AUTOSAR XML (schema 00048)
package /SecurityArchitecture/ComponentTypes
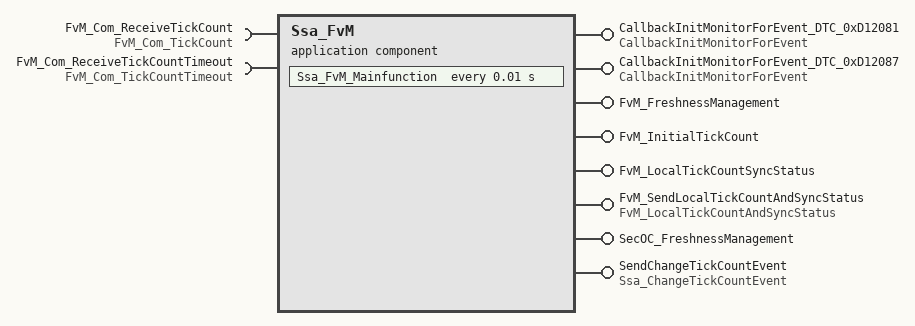
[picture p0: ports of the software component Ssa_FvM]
  application sw component type Ssa_FvM
    8 x provide port:
      CallbackInitMonitorForEvent_DTC_0xD12081: server-com-spec{operation=InitMonitorForEvent, queue-length=1}, provided-interface=CallbackInitMonitorForEvent  # Notifies that this event is cleared, or that the operation (monitoring) cycle restarts. Connect to corresponding event of Dem. Configuration Variant(s): Not in VSM.
      CallbackInitMonitorForEvent_DTC_0xD12087: server-com-spec{operation=InitMonitorForEvent, queue-length=1}, provided-interface=CallbackInitMonitorForEvent  # Notifies that this event is cleared, or that the operation (monitoring) cycle restarts. Connect to corresponding event of Dem. Configuration Variant(s): Not in VSM.
      FvM_FreshnessManagement: provided-com-specs=[{operation=GetRxFreshness, queue-length=1}, {operation=GetTxFreshness, queue-length=1}], provided-interface=FvM_FreshnessManagement
      FvM_InitialTickCount: server-com-spec{operation=Set, queue-length=1}, provided-interface=FvM_InitialTickCount
      FvM_LocalTickCountSyncStatus: server-com-spec{operation=Get, queue-length=1}, provided-interface=FvM_LocalTickCountSyncStatus
      FvM_SendLocalTickCountAndSyncStatus: nonqueued-sender-com-spec{data-element=Data, init-value=constant-reference=Ssa_Init_LocalTickCountAndSyncStatus}, provided-interface=FvM_LocalTickCountAndSyncStatus
      SecOC_FreshnessManagement: provided-interface=SecOC_FreshnessManagement  # Calculates the tick-count as freshness for Rx and Tx PDUs.
        provided-com-specs:
          operation=GetRxFreshness, queue-length=1
          operation=GetTxFreshness, queue-length=1
          operation=GetTxFreshnessTruncData, queue-length=1
          operation=SPduTxConfirmation, queue-length=1
      SendChangeTickCountEvent: provided-interface=Ssa_ChangeTickCountEvent  # Configuration Variant(s): Not in VSM.
        provided-com-specs:
          data-element=Id, init-value=SSA_CHANGETICKCOUNTEVENTID_UNDEFINED
          data-element=TickCount, init-value=constant-reference=Ssa_Init_Zero_5Byte
    require port FvM_Com_ReceiveTickCount: nonqueued-receiver-com-spec{data-element=tickCount, filter=data-filter-type=ALWAYS, init-value=constant-reference=Ssa_Init_Zero_6Byte}, required-interface=FvM_Com_TickCount  # Configuration Variant(s): Not in VSM.
    require port FvM_Com_ReceiveTickCountTimeout: nonqueued-receiver-com-spec{data-element=state, filter=data-filter-type=ALWAYS, init-value=0}, required-interface=FvM_Com_TickCountTimeout  # Configuration Variant(s): Not in VSM.
    behavior Ssa_FvM_InternalBehavior: data-type-mapping=SSATypeMappingSet
      exclusive area FvM_ExclusiveArea
      ar-typed-per-instance-memorys:
        data LastSecuredTickCount: type=uint64
        data TickCount: type=uint64
      data received event DRT_Ssa_TimeM_Com_ReceiveTickCount_FvM_Com_ReceiveTickCount_tickCount: start-on-event=Ssa_FvM_Com_ReceiveTickCount, data=FvM_Com_ReceiveTickCount.tickCount
      data received event DRT_Ssa_FvM_Com_ReceiveTickCountTimeout_FvM_Com_ReceiveTickCountTimeout_state: start-on-event=Ssa_FvM_Com_ReceiveTickCountTimeout, data=FvM_Com_ReceiveTickCountTimeout.state
      5 x operation invoked event:
        OIT_Ssa_FvM_GetRxFreshness_FvM_FreshnessManagement_GetRxFreshness: start-on-event=Ssa_FvM_GetRxFreshness, operation=FvM_FreshnessManagement.GetRxFreshness
        OIT_Ssa_FvM_GetRxFreshness_SecOC_FreshnessManagement_GetRxFreshness: start-on-event=Ssa_FvM_GetRxFreshness, operation=SecOC_FreshnessManagement.GetRxFreshness
        OIT_Ssa_FvM_GetTxFreshness_FvM_FreshnessManagement_GetTxFreshness: start-on-event=Ssa_FvM_GetTxFreshness, operation=FvM_FreshnessManagement.GetTxFreshness
        OIT_Ssa_FvM_GetTxFreshness_SecOC_FreshnessManagement_GetTxFreshness: start-on-event=Ssa_FvM_GetTxFreshness, operation=SecOC_FreshnessManagement.GetTxFreshness
        OIT_Ssa_FvM_GetTxFreshnessTruncData_SecOC_FreshnessManagement_GetTxFreshnessTruncData: start-on-event=Ssa_FvM_GetTxFreshnessTruncData, operation=SecOC_FreshnessManagement.GetTxFreshnessTruncData
      init event Ssa_FvM_InitEvent: start-on-event=Ssa_FvM_Init
      4 x operation invoked event:
        OIT_FvM_InitialTickCount_Set_FvM_InitialTickCount_Set: start-on-event=Ssa_FvM_InitialTickCount_Set, operation=FvM_InitialTickCount.Set
        OIT_CallbackInitMonitorForEvent_DTC_0xD12081_InitMonitorForEvent_CallbackInitMonitorForEvent_DTC_0xD12081_InitMonitorForEvent: start-on-event=Ssa_FvM_InitMonitorForEvent_DTC_0xD12081, operation=CallbackInitMonitorForEvent_DTC_0xD12081.InitMonitorForEvent
        OIT_CallbackInitMonitorForEvent_DTC_0xD12087_InitMonitorForEvent_CallbackInitMonitorForEvent_DTC_0xD12087_InitMonitorForEvent: start-on-event=Ssa_FvM_InitMonitorForEvent_DTC_0xD12087, operation=CallbackInitMonitorForEvent_DTC_0xD12087.InitMonitorForEvent
        OIT_FvM_LocalTickCountSyncStatus_Get_FvM_LocalTickCountSyncStatus_Get: start-on-event=Ssa_FvM_LocalTickCountSyncStatus_Get, operation=FvM_LocalTickCountSyncStatus.Get
      timing event TMT_Ssa_FvM_Mainfunction: start-on-event=Ssa_FvM_Mainfunction, period=0.01
      operation invoked event OIT_Ssa_FvM_SPduTxConfirmation_SecOC_FreshnessManagement_SPduTxConfirmation: start-on-event=Ssa_FvM_SPduTxConfirmation, operation=SecOC_FreshnessManagement.SPduTxConfirmation
      explicit-inter-runnable-variables:
        data FvM_IrvCountUpSecTimeMsg: type=uint8, init-value=0
        data FvM_IrvFirstTickCountMessageAfterStartUpReceived: type=boolean, init-value=0
        data FvM_IrvTickCountSyncState: type=Ssa_TickCountSyncStateType, init-value=0
      12 x runnable:
        Ssa_FvM_Com_ReceiveTickCount: can-enter-exclusive-area=FvM_ExclusiveArea  # Check if the received time is valid. If it is valid, update the Local Time Base. Function is called when the Time Base Signal is received. Configuration Variant(s): Not in VSM.
          data-receive-point-by-arguments:
            access REC_FvM_Com_ReceiveTickCount_tickCount: accessed-variable=FvM_Com_ReceiveTickCount.tickCount
          data-send-points:
            access SEND_SendChangeTickCountEvent_Event: accessed-variable=SendChangeTickCountEvent.Id
            access SEND_SendChangeTickCountEvent_TickCount: accessed-variable=SendChangeTickCountEvent.TickCount
          read-local-variables:
            access READ_FvM_IrvFirstTickCountMessageAfterStartUpReceived: accessed-variable=FvM_IrvFirstTickCountMessageAfterStartUpReceived
          written-local-variables:
            access WRITE_FvM_IrvFirstTickCountMessageAfterStartUpReceived: accessed-variable=FvM_IrvFirstTickCountMessageAfterStartUpReceived
            access WRITE_FvM_IrvTickCountSyncState: accessed-variable=FvM_IrvTickCountSyncState
        Ssa_FvM_Com_ReceiveTickCountTimeout  # Configuration Variant(s): Not in VSM.
        Ssa_FvM_GetRxFreshness: can-enter-exclusive-area=FvM_ExclusiveArea, can-be-invoked-concurrently=true
        Ssa_FvM_GetTxFreshness: can-enter-exclusive-area=FvM_ExclusiveArea, can-be-invoked-concurrently=true
        Ssa_FvM_GetTxFreshnessTruncData: can-enter-exclusive-area=FvM_ExclusiveArea, can-be-invoked-concurrently=true
        Ssa_FvM_Init
          data-send-points:
            access SEND_FvM_SendLocalTickCountAndSyncStatus_Data: accessed-variable=FvM_SendLocalTickCountAndSyncStatus.Data
          written-local-variables:
            access WRITE_FvM_IrvCountUpSecTimeMsg: accessed-variable=FvM_IrvCountUpSecTimeMsg
            access WRITE_FvM_IrvFirstTickCountMessageAfterStartUpReceived: accessed-variable=FvM_IrvFirstTickCountMessageAfterStartUpReceived
            access WRITE_FvM_IrvTickCountSyncState: accessed-variable=FvM_IrvTickCountSyncState
        Ssa_FvM_InitialTickCount_Set: can-enter-exclusive-area=FvM_ExclusiveArea, can-be-invoked-concurrently=true
        Ssa_FvM_InitMonitorForEvent_DTC_0xD12081  # Configuration Variant(s): Not in VSM.
        Ssa_FvM_InitMonitorForEvent_DTC_0xD12087  # Configuration Variant(s): Not in VSM.
        Ssa_FvM_LocalTickCountSyncStatus_Get: can-be-invoked-concurrently=true
          read-local-variables:
            access READ_FvM_IrvTickCountSyncState: accessed-variable=FvM_IrvTickCountSyncState
        Ssa_FvM_Mainfunction: can-enter-exclusive-area=FvM_ExclusiveArea
          data-send-points:
            access SEND_FvM_SendLocalTickCountAndSyncStatus_Data: accessed-variable=FvM_SendLocalTickCountAndSyncStatus.Data
            access SEND_SendChangeTickCountEvent_Event: accessed-variable=SendChangeTickCountEvent.Id
            access SEND_SendChangeTickCountEvent_TickCount: accessed-variable=SendChangeTickCountEvent.TickCount
          read-local-variables:
            access READ_FvM_IrvCountUpSecTimeMsg: accessed-variable=FvM_IrvCountUpSecTimeMsg
            access READ_FvM_IrvTickCountSyncState: accessed-variable=FvM_IrvTickCountSyncState
          written-local-variables:
            access WRITE_FvM_IrvCountUpSecTimeMsg: accessed-variable=FvM_IrvCountUpSecTimeMsg
            access WRITE_FvM_IrvTickCountSyncState: accessed-variable=FvM_IrvTickCountSyncState
        Ssa_FvM_SPduTxConfirmation: can-be-invoked-concurrently=true
  swc implementation Ssa_FvM_Implementation: behavior=Ssa_FvM_InternalBehavior
    code-descriptors:
      code Default: artifact-descriptors=autosar-engineering-object=category=SWSRC
